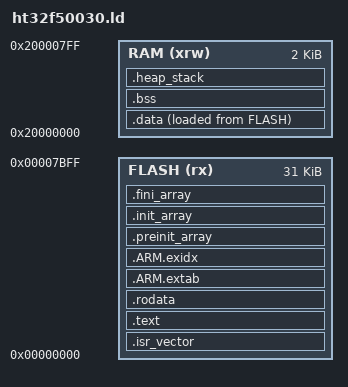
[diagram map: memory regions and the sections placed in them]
ENTRY(Reset_Handler)

MEMORY
{
  FLASH (rx)  : ORIGIN = 0x00000000, LENGTH = 31K
  RAM   (xrw) : ORIGIN = 0x20000000, LENGTH = 2K
}

SECTIONS
{
  .isr_vector :
  {
    . = ALIGN(4);
    KEEP(*(.isr_vector))
    . = ALIGN(4);
  } > FLASH

  .text :
  {
    . = ALIGN(4);
    *(.text)
    *(.text*)
    *(.glue_7)
    *(.glue_7t)
    *(.eh_frame)
    KEEP(*(.init))
    KEEP(*(.fini))
    . = ALIGN(4);
  } > FLASH

  .rodata :
  {
    . = ALIGN(4);
    *(.rodata)
    *(.rodata*)
    . = ALIGN(4);
  } > FLASH

  .ARM.extab :
  {
    *(.ARM.extab*)
    *(.gnu.linkonce.armextab.*)
  } > FLASH

  .ARM.exidx :
  {
    __exidx_start = .;
    *(.ARM.exidx*)
    __exidx_end = .;
  } > FLASH

  .preinit_array :
  {
    PROVIDE_HIDDEN(__preinit_array_start = .);
    KEEP(*(.preinit_array*))
    PROVIDE_HIDDEN(__preinit_array_end = .);
  } > FLASH

  .init_array :
  {
    PROVIDE_HIDDEN(__init_array_start = .);
    KEEP(*(SORT(.init_array.*)))
    KEEP(*(.init_array*))
    PROVIDE_HIDDEN(__init_array_end = .);
  } > FLASH

  .fini_array :
  {
    PROVIDE_HIDDEN(__fini_array_start = .);
    KEEP(*(SORT(.fini_array.*)))
    KEEP(*(.fini_array*))
    PROVIDE_HIDDEN(__fini_array_end = .);
  } > FLASH

  . = ALIGN(4);
  __etext = .;
  _etext = .;
  _sidata = LOADADDR(.data);

  .data :
  {
    . = ALIGN(4);
    _sdata = .;
    *(.data)
    *(.data*)
    . = ALIGN(4);
    _edata = .;
  } > RAM AT > FLASH

  .bss :
  {
    . = ALIGN(4);
    _sbss = .;
    __bss_start__ = _sbss;
    *(.bss)
    *(.bss*)
    *(COMMON)
    . = ALIGN(4);
    _ebss = .;
    __bss_end__ = _ebss;
  } > RAM

  .heap_stack (NOLOAD) :
  {
    . = ALIGN(8);
    __heap_stack_start__ = .;
    *(.heap)
    *(.stack)
    . = ALIGN(8);
    __heap_stack_end__ = .;
    _end = .;
    __end__ = .;
  } > RAM

  /DISCARD/ :
  {
    *(.note.GNU-stack)
    *(.comment)
  }

  .ARM.attributes 0 : { *(.ARM.attributes) }
}

ASSERT(__etext <= ORIGIN(FLASH) + LENGTH(FLASH), "FLASH overflow")
ASSERT(__heap_stack_end__ <= ORIGIN(RAM) + LENGTH(RAM), "RAM overflow")
